# ATSAM4LS8A device description
Architecture: CORTEX-M4; Family: SAM4; Series: SAM4L
Registers are 32-bit, read-write, reset 0x0 unless marked. A register's access mark holds for its fields unless they carry their own. Offsets are from the block's base; [hi:lo] are bit positions; {n}, {i} and the like mark numbered series; 'fields as' and 'values as' point back to an identical list.

## FLASHCALW — Flash Controller
Instances: HFLASHC 0x400A0000
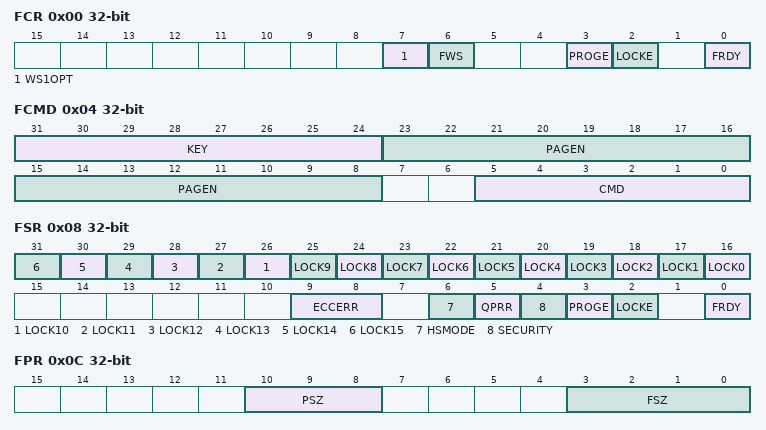
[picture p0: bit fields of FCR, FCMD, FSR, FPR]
0x00 FCR — Flash Controller Control Register
  [7] WS1OPT — Wait State 1 Optimization
  [6] FWS — Flash Wait State
    0=The flash is read with 0 wait states; 1=The flash is read with 1 wait states
  [3] PROGE — Programming Error Interrupt Enable
    0=Programming Error does not generate an interrupt; 1=Programming Error generates an interrupt
  [2] LOCKE — Lock Error Interrupt Enable
    0=Lock Error does not generate an interrupt; 1=Lock Error generates an interrupt
  [0] FRDY — Flash Ready Interrupt Enable
    0=Flash Ready does not generate an interrupt; 1=Flash Ready generates an interrupt
0x04 FCMD — Flash Controller Command Register
  [31:24] KEY — Write protection key
    165=KEY
  [23:8] PAGEN — Page number
  [5:0] CMD — Command
    0=NOP (No Operation); 1=WP (Write Page); 2=EP (Erase Page); 3=CPB (Clear Page Buffer); 4=LP (Lock Region containing page); 5=UP (Unlock Region containing page); 6=EA (Erase All, including secuity and fuse bits); 7=WGPB (Write General-Purpose fuse Bit); 8=EGPB (Erase General-Purpose fuse Bit); 9=SSB (Set Security Bit); 10=PGPFB (Program GPFuse Byte); 11=EAGPF (Erase All GP Fuses); 12=QPR (Quick Page Read); 13=WUP (Write User Page); 14=EUP (Erase User Page); 15=QPRUP (Quick Page Read User Page); 16=HSEN (High Speed Mode Enable); 17=HSDIS (High Speed Mode Disable)
0x08 FSR — Flash Controller Status Register
  [n+16] LOCK{n} (n=0..15) — Lock Region {n} Lock Status
  [9:8] ECCERR — ECC Error Status
    0=NOERROR; 1=ONEECCERR (One ECC error detected); 2=TWOECCERR (Two ECC errors detected)
  [6] HSMODE — High Speed Mode
  [5] QPRR — Quick Page Read Result
  [4] SECURITY — Security Bit Status
  [3] PROGE — Programming Error Status
  [2] LOCKE — Lock Error Status
  [0] FRDY — Flash Ready Status
0x0C FPR ro reset not defined — Flash Controller Parameter Register
  [10:8] PSZ — Page Size
  [3:0] FSZ — Flash Size
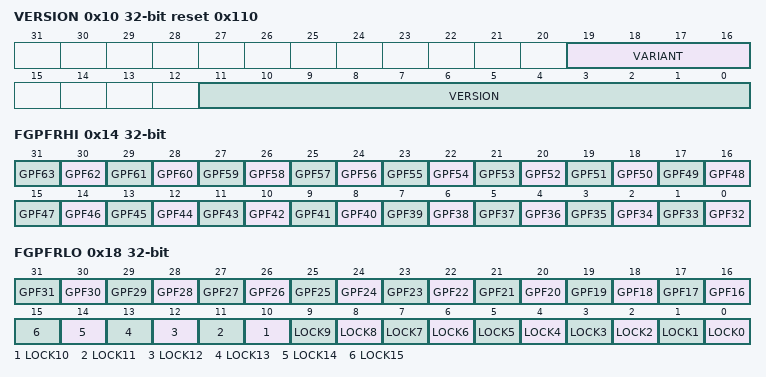
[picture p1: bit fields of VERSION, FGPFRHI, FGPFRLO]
0x10 VERSION ro reset 0x110 — Flash Controller Version Register
  [19:16] VARIANT — Variant Number
  [11:0] VERSION — Version Number
0x14 FGPFRHI reset not defined — Flash Controller General Purpose Fuse Register High
  [n-32] GPF{n} (n=32..63) — General Purpose Fuse {n}
0x18 FGPFRLO reset not defined — Flash Controller General Purpose Fuse Register Low
  [n] GPF{n} (n=16..31) — General Purpose Fuse {n}
  [n] LOCK{n} (n=0..15) — Lock Bit {n}

## USERPAGE_FUSES — Non-Volatile Fuses
Instances: USERPAGE_FUSES 0x00800000
0x00 USERPAGE_WORD_1 reset 0xFFFFFFFF
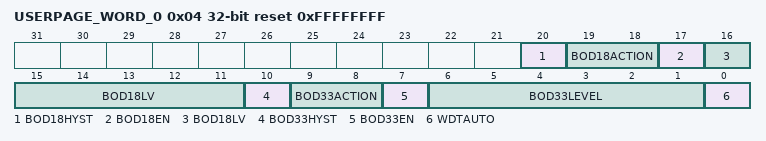
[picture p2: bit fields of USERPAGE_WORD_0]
0x04 USERPAGE_WORD_0 reset 0xFFFFFFFF
  [20] BOD18HYST — 1v8 Brown Out Detector Hysteresis
    0=BOD_HYST_DISABLED (Disabled); 1=BOD_HYST_ENABLED (Enabled)
  [19:18] BOD18ACTION — 1v8 Brown Out Detector Action
    0=BOD_ACTION_NOACTION (BOD No Action); 1=BOD_ACTION_GENERATE_RESET (The BOD generates a reset); 2=BOD_ACTION_GENERATE_INTERRUPT (The BOD generates an interrupt); 3=BOD_ACTION_RESERVED (Reserved)
  [17] BOD18EN — 1v8 Brown Out Detector Enable
    0=BOD_DISABLED; 1=BOD_ENABLED
  [16:11] BOD18LV — 1v8 Brown Out Detector Level
    0=BOD_LEVEL_OFF; 31=BOD_LEVEL_1V56 (BOD Level 1.56V); 39=BOD_LEVEL_1V65 (BOD Level 1.65V)
  [10] BOD33HYST — 3v3 Brown Out Detector Hysteresis
    0=BOD_HYST_DISABLED (Disabled); 1=BOD_HYST_ENABLED (Enabled)
  [9:8] BOD33ACTION — 3v3 Brown Out Detector Action
    values as BOD18ACTION
  [7] BOD33EN — 3v3 Brown Out Detector Enable
    0=BOD_DISABLED; 1=BOD_ENABLED
  [6:1] BOD33LEVEL — 3v3 Brown Out Detector Level
    values as BOD18LV
  [0] WDTAUTO — Watch dog timer auto enable/disable at startup
    0=WDT_ENABLE (WDT is automatically enabled at startup); 1=WDT_DISABLE (WDT is not automatically enabled at startup)

## Notices in the file
Copyright (c) 2016 Atmel Corporation,
a wholly owned subsidiary of Microchip Technology Inc.
Licensed under the Apache License, Version 2.0 (the "License");
you may not use this file except in compliance with the License.
You may obtain a copy of the Licence at
http://www.apache.org/licenses/LICENSE-2.0
Unless required by applicable law or agreed to in writing, software
distributed under the License is distributed on an "AS IS" BASIS,
WITHOUT WARRANTIES OR CONDITIONS OF ANY KIND, either express or implied.
See the License for the specific language governing permissions and
limitations under the License.
